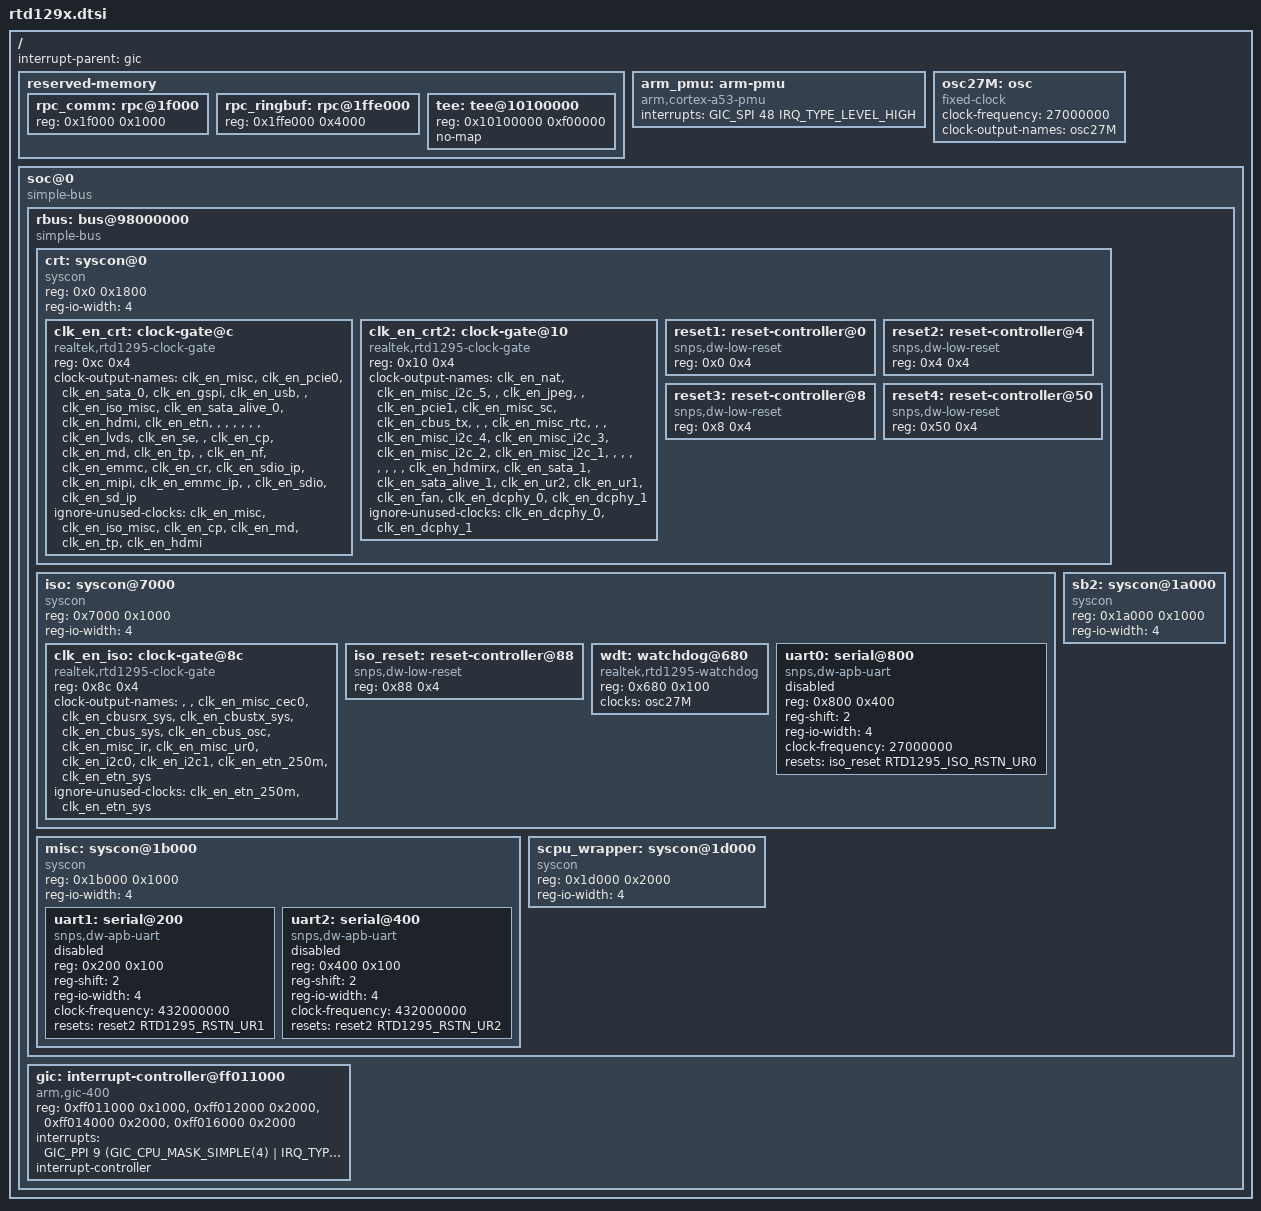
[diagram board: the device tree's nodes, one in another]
// SPDX-License-Identifier: (GPL-2.0-or-later OR BSD-2-Clause)
/*
 * Realtek RTD1293/RTD1295/RTD1296 SoC
 *
 * Copyright (c) 2016-2019 Andreas Färber
 */

/memreserve/	0x0000000000000000 0x000000000001f000;
/memreserve/	0x000000000001f000 0x00000000000e1000;
/memreserve/	0x0000000001b00000 0x00000000004be000;

#include <dt-bindings/interrupt-controller/arm-gic.h>
#include <dt-bindings/reset/realtek,rtd1295.h>

/ {
	interrupt-parent = <&gic>;
	#address-cells = <1>;
	#size-cells = <1>;

	reserved-memory {
		#address-cells = <1>;
		#size-cells = <1>;
		ranges;

		rpc_comm: rpc@1f000 {
			reg = <0x1f000 0x1000>;
		};

		rpc_ringbuf: rpc@1ffe000 {
			reg = <0x1ffe000 0x4000>;
		};

		tee: tee@10100000 {
			reg = <0x10100000 0xf00000>;
			no-map;
		};
	};

	arm_pmu: arm-pmu {
		compatible = "arm,cortex-a53-pmu";
		interrupts = <GIC_SPI 48 IRQ_TYPE_LEVEL_HIGH>;
	};

	osc27M: osc {
		compatible = "fixed-clock";
		clock-frequency = <27000000>;
		#clock-cells = <0>;
		clock-output-names = "osc27M";
	};

	soc@0 {
		compatible = "simple-bus";
		#address-cells = <1>;
		#size-cells = <1>;
		ranges = <0x00000000 0x00000000 0x0001f000>, /* boot ROM */
			 /* Exclude up to 2 GiB of RAM */
			 <0x80000000 0x80000000 0x80000000>;

		rbus: bus@98000000 {
			compatible = "simple-bus";
			#address-cells = <1>;
			#size-cells = <1>;
			ranges = <0x0 0x98000000 0x200000>,
				 /* PCIe MMIO windows (slot1 0xc0000000, slot2 0xc1000000) */
				 <0xc0000000 0xc0000000 0x02000000>;

			crt: syscon@0 {
				compatible = "syscon", "simple-mfd";
				reg = <0x0 0x1800>;
				reg-io-width = <4>;
				#address-cells = <1>;
				#size-cells = <1>;
				ranges = <0x0 0x0 0x1800>;

				/*
				 * Clock gates.  One 32-bit register each, one
				 * bit per clock, so the index in a consumer's
				 * "clocks" phandle is the bit number.  Names
				 * and ignore-unused lists are taken verbatim
				 * from the DTB of the 4.9 vendor kernel that
				 * shipped on this machine; an empty string
				 * marks a bit that is not implemented.
				 */
				clk_en_crt: clock-gate@c {
					compatible = "realtek,rtd1295-clock-gate";
					reg = <0xc 0x4>;
					#clock-cells = <1>;
					clock-output-names =
						"clk_en_misc", "clk_en_pcie0",
						"clk_en_sata_0", "clk_en_gspi",
						"clk_en_usb", "",
						"clk_en_iso_misc", "clk_en_sata_alive_0",
						"clk_en_hdmi", "clk_en_etn",
						"", "", "", "", "", "",
						"clk_en_lvds", "clk_en_se",
						"", "clk_en_cp",
						"clk_en_md", "clk_en_tp",
						"", "clk_en_nf",
						"clk_en_emmc", "clk_en_cr",
						"clk_en_sdio_ip", "clk_en_mipi",
						"clk_en_emmc_ip", "",
						"clk_en_sdio", "clk_en_sd_ip";
					ignore-unused-clocks =
						"clk_en_misc", "clk_en_iso_misc",
						"clk_en_cp", "clk_en_md",
						"clk_en_tp", "clk_en_hdmi";
				};

				clk_en_crt2: clock-gate@10 {
					compatible = "realtek,rtd1295-clock-gate";
					reg = <0x10 0x4>;
					#clock-cells = <1>;
					clock-output-names =
						"clk_en_nat", "clk_en_misc_i2c_5",
						"", "clk_en_jpeg",
						"", "clk_en_pcie1",
						"clk_en_misc_sc", "clk_en_cbus_tx",
						"", "",
						"clk_en_misc_rtc", "", "",
						"clk_en_misc_i2c_4", "clk_en_misc_i2c_3",
						"clk_en_misc_i2c_2", "clk_en_misc_i2c_1",
						"", "", "", "", "", "", "",
						"clk_en_hdmirx", "clk_en_sata_1",
						"clk_en_sata_alive_1", "clk_en_ur2",
						"clk_en_ur1", "clk_en_fan",
						"clk_en_dcphy_0", "clk_en_dcphy_1";
					ignore-unused-clocks =
						"clk_en_dcphy_0", "clk_en_dcphy_1";
				};
			};

			iso: syscon@7000 {
				compatible = "syscon", "simple-mfd";
				reg = <0x7000 0x1000>;
				reg-io-width = <4>;
				#address-cells = <1>;
				#size-cells = <1>;
				ranges = <0x0 0x7000 0x1000>;

				/* 0x9800708c in the 4.9 DTB. i2c0/i2c1 live here. */
				clk_en_iso: clock-gate@8c {
					compatible = "realtek,rtd1295-clock-gate";
					reg = <0x8c 0x4>;
					#clock-cells = <1>;
					clock-output-names =
						"", "",
						"clk_en_misc_cec0", "clk_en_cbusrx_sys",
						"clk_en_cbustx_sys", "clk_en_cbus_sys",
						"clk_en_cbus_osc", "clk_en_misc_ir",
						"clk_en_misc_ur0", "clk_en_i2c0",
						"clk_en_i2c1", "clk_en_etn_250m",
						"clk_en_etn_sys";
					ignore-unused-clocks =
						"clk_en_etn_250m", "clk_en_etn_sys";
				};
			};

			sb2: syscon@1a000 {
				compatible = "syscon", "simple-mfd";
				reg = <0x1a000 0x1000>;
				reg-io-width = <4>;
				#address-cells = <1>;
				#size-cells = <1>;
				ranges = <0x0 0x1a000 0x1000>;
			};

			misc: syscon@1b000 {
				compatible = "syscon", "simple-mfd";
				reg = <0x1b000 0x1000>;
				reg-io-width = <4>;
				#address-cells = <1>;
				#size-cells = <1>;
				ranges = <0x0 0x1b000 0x1000>;
			};

			scpu_wrapper: syscon@1d000 {
				compatible = "syscon", "simple-mfd";
				reg = <0x1d000 0x2000>;
				reg-io-width = <4>;
				#address-cells = <1>;
				#size-cells = <1>;
				ranges = <0x0 0x1d000 0x2000>;
			};
		};

		gic: interrupt-controller@ff011000 {
			compatible = "arm,gic-400";
			reg = <0xff011000 0x1000>,
			      <0xff012000 0x2000>,
			      <0xff014000 0x2000>,
			      <0xff016000 0x2000>;
			interrupts = <GIC_PPI 9 (GIC_CPU_MASK_SIMPLE(4) | IRQ_TYPE_LEVEL_LOW)>;
			interrupt-controller;
			#interrupt-cells = <3>;
		};
	};
};

&crt {
	reset1: reset-controller@0 {
		compatible = "snps,dw-low-reset";
		reg = <0x0 0x4>;
		#reset-cells = <1>;
	};

	reset2: reset-controller@4 {
		compatible = "snps,dw-low-reset";
		reg = <0x4 0x4>;
		#reset-cells = <1>;
	};

	reset3: reset-controller@8 {
		compatible = "snps,dw-low-reset";
		reg = <0x8 0x4>;
		#reset-cells = <1>;
	};

	reset4: reset-controller@50 {
		compatible = "snps,dw-low-reset";
		reg = <0x50 0x4>;
		#reset-cells = <1>;
	};
};

&iso {
	iso_reset: reset-controller@88 {
		compatible = "snps,dw-low-reset";
		reg = <0x88 0x4>;
		#reset-cells = <1>;
	};

	wdt: watchdog@680 {
		compatible = "realtek,rtd1295-watchdog";
		reg = <0x680 0x100>;
		clocks = <&osc27M>;
	};

	uart0: serial@800 {
		compatible = "snps,dw-apb-uart";
		reg = <0x800 0x400>;
		reg-shift = <2>;
		reg-io-width = <4>;
		clock-frequency = <27000000>;
		resets = <&iso_reset RTD1295_ISO_RSTN_UR0>;
		status = "disabled";
	};
};

&misc {
	uart1: serial@200 {
		compatible = "snps,dw-apb-uart";
		reg = <0x200 0x100>;
		reg-shift = <2>;
		reg-io-width = <4>;
		clock-frequency = <432000000>;
		resets = <&reset2 RTD1295_RSTN_UR1>;
		status = "disabled";
	};

	uart2: serial@400 {
		compatible = "snps,dw-apb-uart";
		reg = <0x400 0x100>;
		reg-shift = <2>;
		reg-io-width = <4>;
		clock-frequency = <432000000>;
		resets = <&reset2 RTD1295_RSTN_UR2>;
		status = "disabled";
	};
};
